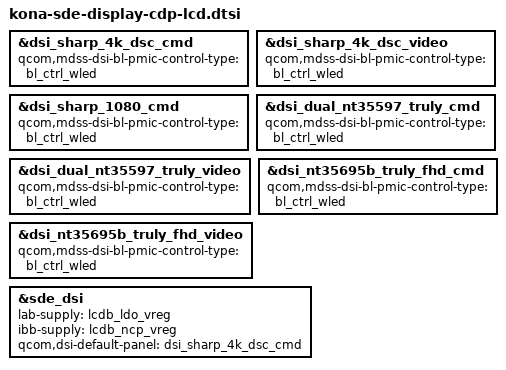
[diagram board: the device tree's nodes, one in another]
&dsi_sharp_4k_dsc_cmd {
	qcom,mdss-dsi-bl-pmic-control-type = "bl_ctrl_wled";
	/delete-property/ qcom,platform-en-gpio;
};

&dsi_sharp_4k_dsc_video {
	qcom,mdss-dsi-bl-pmic-control-type = "bl_ctrl_wled";
	/delete-property/ qcom,platform-en-gpio;
};

&dsi_sharp_1080_cmd {
	qcom,mdss-dsi-bl-pmic-control-type = "bl_ctrl_wled";
};

&dsi_dual_nt35597_truly_cmd {
	qcom,mdss-dsi-bl-pmic-control-type = "bl_ctrl_wled";
};

&dsi_dual_nt35597_truly_video {
	qcom,mdss-dsi-bl-pmic-control-type = "bl_ctrl_wled";
};

&dsi_nt35695b_truly_fhd_cmd {
	qcom,mdss-dsi-bl-pmic-control-type = "bl_ctrl_wled";
};

&dsi_nt35695b_truly_fhd_video {
	qcom,mdss-dsi-bl-pmic-control-type = "bl_ctrl_wled";
};

&sde_dsi {
	/delete-property/ avdd-supply;
	lab-supply = <&lcdb_ldo_vreg>;
	ibb-supply = <&lcdb_ncp_vreg>;
	qcom,dsi-default-panel = <&dsi_sharp_4k_dsc_cmd>;
};
